AUTOSAR XML (schema 4-0-3)
package /ComponentTypes
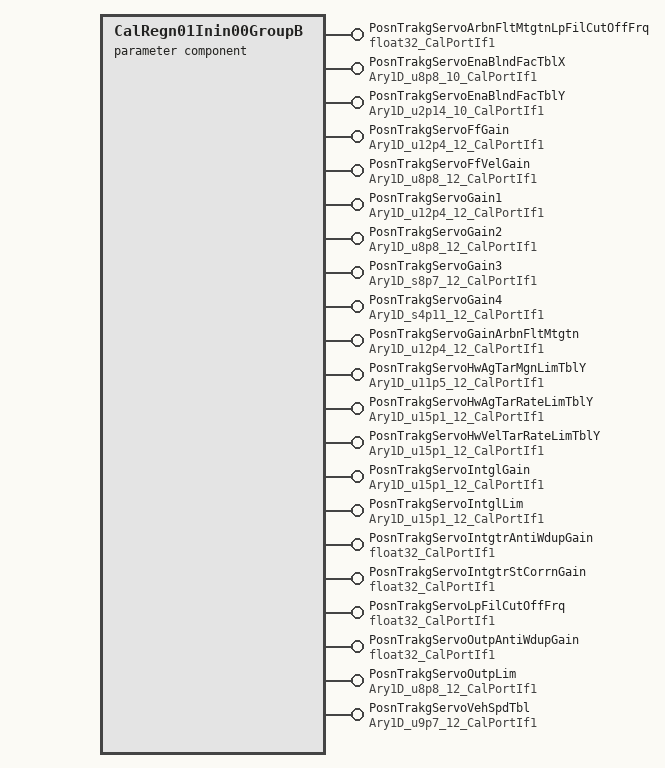
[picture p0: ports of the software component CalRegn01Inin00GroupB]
  parameter sw component type CalRegn01Inin00GroupB
    21 x provide port:
      PosnTrakgServoArbnFltMtgtnLpFilCutOffFrq: parameter-provide-com-spec{init-value=1, parameter=Val}, provided-interface=float32_CalPortIf1
      PosnTrakgServoEnaBlndFacTblX: parameter-provide-com-spec{init-value=[0, 26, 51, 77, 128, 256, 512, 768, 1024, 2560], parameter=Ary1D}, provided-interface=Ary1D_u8p8_10_CalPortIf1
      PosnTrakgServoEnaBlndFacTblY: parameter-provide-com-spec{init-value=[0, 164, 328, 819, 1638, 3277, 8192, 11469, 16384, 16384], parameter=Ary1D}, provided-interface=Ary1D_u2p14_10_CalPortIf1
      PosnTrakgServoFfGain: parameter-provide-com-spec{init-value=12 x 0, parameter=Ary1D}, provided-interface=Ary1D_u12p4_12_CalPortIf1
      PosnTrakgServoFfVelGain: parameter-provide-com-spec{init-value=12 x 0, parameter=Ary1D}, provided-interface=Ary1D_u8p8_12_CalPortIf1
      PosnTrakgServoGain1: parameter-provide-com-spec{init-value=12 x 16261, parameter=Ary1D}, provided-interface=Ary1D_u12p4_12_CalPortIf1
      PosnTrakgServoGain2: parameter-provide-com-spec{init-value=12 x 5780, parameter=Ary1D}, provided-interface=Ary1D_u8p8_12_CalPortIf1
      PosnTrakgServoGain3: parameter-provide-com-spec{init-value=12 x -326, parameter=Ary1D}, provided-interface=Ary1D_s8p7_12_CalPortIf1
      PosnTrakgServoGain4: parameter-provide-com-spec{init-value=12 x 222, parameter=Ary1D}, provided-interface=Ary1D_s4p11_12_CalPortIf1
      PosnTrakgServoGainArbnFltMtgtn: parameter-provide-com-spec{init-value=[960, 960, 800, 640, 480, 320, 320, 160, 160, 160, 160, 160], parameter=Ary1D}, provided-interface=Ary1D_u12p4_12_CalPortIf1
      PosnTrakgServoHwAgTarMgnLimTblY: parameter-provide-com-spec{init-value=[4480, 14400, 11520, 5760, 5760, 5760, 5760, 5760, 5760, 5760, 5760, 5760], parameter=Ary1D}, provided-interface=Ary1D_u11p5_12_CalPortIf1
      PosnTrakgServoHwAgTarRateLimTblY: parameter-provide-com-spec{init-value=12 x 45000, parameter=Ary1D}, provided-interface=Ary1D_u15p1_12_CalPortIf1
      PosnTrakgServoHwVelTarRateLimTblY: parameter-provide-com-spec{init-value=12 x 45000, parameter=Ary1D}, provided-interface=Ary1D_u15p1_12_CalPortIf1
      PosnTrakgServoIntglGain: parameter-provide-com-spec{init-value=12 x 23464, parameter=Ary1D}, provided-interface=Ary1D_u15p1_12_CalPortIf1
      PosnTrakgServoIntglLim: parameter-provide-com-spec{init-value=[24000, 20000, 16000, 12000, 8000, 8000, 8000, 8000, 8000, 8000, 8000, 8000], parameter=Ary1D}, provided-interface=Ary1D_u15p1_12_CalPortIf1
      PosnTrakgServoIntgtrAntiWdupGain: parameter-provide-com-spec{init-value=0, parameter=Val}, provided-interface=float32_CalPortIf1
      PosnTrakgServoIntgtrStCorrnGain: parameter-provide-com-spec{init-value=0.1, parameter=Val}, provided-interface=float32_CalPortIf1
      PosnTrakgServoLpFilCutOffFrq: parameter-provide-com-spec{init-value=250, parameter=Val}, provided-interface=float32_CalPortIf1
      PosnTrakgServoOutpAntiWdupGain: parameter-provide-com-spec{init-value=0, parameter=Val}, provided-interface=float32_CalPortIf1
      PosnTrakgServoOutpLim: parameter-provide-com-spec{init-value=12 x 32000, parameter=Ary1D}, provided-interface=Ary1D_u8p8_12_CalPortIf1
      PosnTrakgServoVehSpdTbl: parameter-provide-com-spec{init-value=[0, 1280, 2560, 3840, 5120, 6400, 7680, 8960, 10240, 11520, 12800, 14080], parameter=Ary1D}, provided-interface=Ary1D_u9p7_12_CalPortIf1
